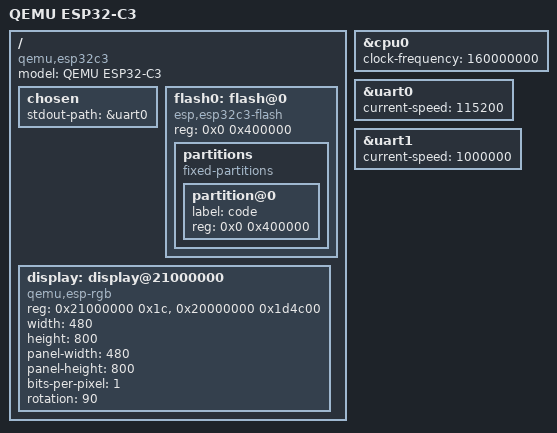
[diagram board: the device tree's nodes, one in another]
// SPDX-FileCopyrightText: 2026 Core Devices LLC
// SPDX-License-Identifier: (GPL-2.0-only OR BSD-2-Clause)

/dts-v1/;

// Espressif's QEMU esp32c3 machine, booting the flash image through the ESP32-C3 ROM, with
// UART0 for the console

#include "espressif/esp32c3.dtsi"

/ {
	model = "QEMU ESP32-C3";
	compatible = "qemu,esp32c3", "esp,esp32c3";

	chosen {
		stdout-path = &uart0;
	};

	// The flash the ROM maps, an emulated SPI NOR
	flash0: flash@0 {
		compatible = "esp,esp32c3-flash";
		reg = <0x0 0x400000>;

		partitions {
			compatible = "fixed-partitions";
			#address-cells = <1>;
			#size-cells = <1>;

			// Where the ROM boots from
			partition@0 {
				label = "code";
				reg = <0x0 0x400000>;
			};
		};
	};
};

// The machine counts cycles at 160 MHz whatever the clocks
&cpu0 {
	clock-frequency = <160000000>;
};

&uart0 {
	current-speed = <115200>;
	status = "okay";
};

// The H4 Bluetooth controller of CONFIG_NIMBLE_HCI_UART, the machine's second -serial
&uart1 {
	current-speed = <1000000>;
	status = "okay";
};

/ {
	// The machine's virtual RGB framebuffer, emulating the 800x480 e-paper of the Xteink X4 mounted
	// in portrait, so the window shows it sideways as its controller scans it
	display: display@21000000 {
		compatible = "qemu,esp-rgb";
		reg = <0x21000000 0x1c>, <0x20000000 0x1d4c00>;
		reg-names = "regs", "vram";
		width = <480>;
		height = <800>;
		panel-width = <480>;
		panel-height = <800>;
		bits-per-pixel = <1>;
		rotation = <90>;
	};
};
